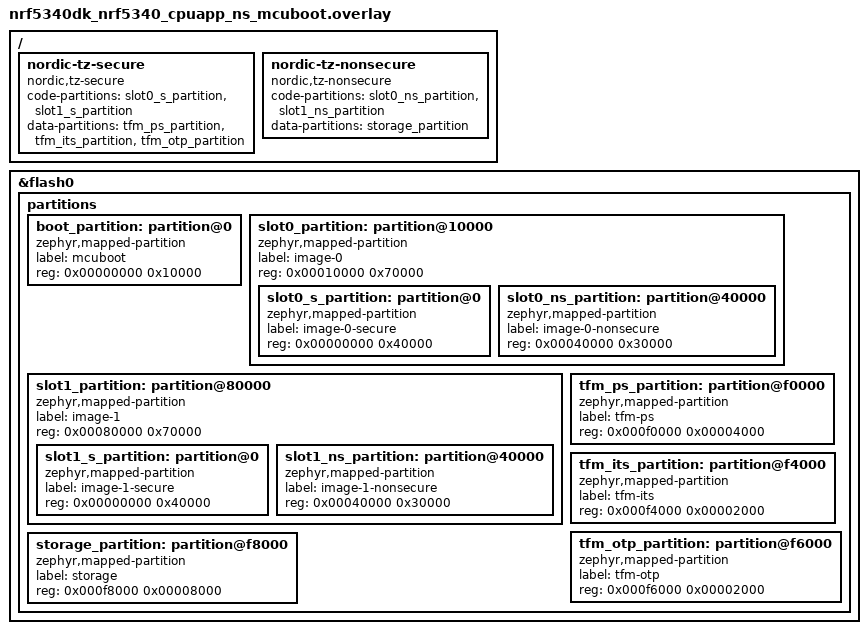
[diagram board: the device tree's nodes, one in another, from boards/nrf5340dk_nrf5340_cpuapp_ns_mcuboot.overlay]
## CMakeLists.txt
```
#
# Copyright (c) 2021 Nordic Semiconductor ASA
#
# SPDX-License-Identifier: LicenseRef-Nordic-5-Clause
#

cmake_minimum_required(VERSION 3.20.0)

if(NOT crypto_service IN_LIST SNIPPET)
  set(SNIPPET crypto_service ${SNIPPET} CACHE STRING "" FORCE)
endif()

find_package(Zephyr REQUIRED HINTS $ENV{ZEPHYR_BASE})

project(sha256)

target_sources(app PRIVATE
        src/main.c)
```

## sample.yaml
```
sample:
  description: |
    This sample demonstrates hash computation and verification using the SHA-256 hash algorithm.
  name: SHA-256 sample
common:
  sysbuild: true
  tags:
    - introduction
    - psa
    - sysbuild
    - ci_samples_crypto
    - crypto
  harness: console
  harness_config:
    type: multi_line
    regex:
      - ".*Example finished successfully!.*"
tests:
  sample.sha256.cc3xx:
    tags:
      - cc3xx
    platform_allow:
      - nrf5340dk/nrf5340/cpuapp/ns
      - nrf5340dk/nrf5340/cpuapp
      - nrf9151dk/nrf9151
      - nrf9151dk/nrf9151/ns
    integration_platforms:
      - nrf5340dk/nrf5340/cpuapp/ns
      - nrf5340dk/nrf5340/cpuapp
      - nrf9151dk/nrf9151
      - nrf9151dk/nrf9151/ns
  sample.sha256.oberon:
    extra_args:
      - CONFIG_PSA_CRYPTO_DRIVER_OBERON=y
      - CONFIG_PSA_CRYPTO_DRIVER_CRACEN=n
    tags:
      - oberon
    platform_allow:
      - nrf5340dk/nrf5340/cpunet
      - nrf54l15dk/nrf54l15/cpuapp
    integration_platforms:
      - nrf5340dk/nrf5340/cpunet
      - nrf54l15dk/nrf54l15/cpuapp
  sample.sha256.cracen:
    tags:
      - cracen
    platform_allow:
      - nrf54l15dk/nrf54l15/cpuapp
      - nrf54l15dk/nrf54l15/cpuapp/ns
      - nrf54l15dk/nrf54l10/cpuapp
      - nrf54l15dk/nrf54l10/cpuapp/ns
      - nrf54l15dk/nrf54l05/cpuapp
      - nrf54ls05dk/nrf54ls05a/cpuapp
      - nrf54ls05dk/nrf54ls05b/cpuapp
      - nrf54lm20dk/nrf54lm20a/cpuapp
      - nrf54lm20dk/nrf54lm20a/cpuapp/ns
      - nrf54lm20dk/nrf54lm20b/cpuapp
      - nrf54lm20dk/nrf54lm20b/cpuapp/ns
      - nrf54lv10dk/nrf54lv10a/cpuapp
      - nrf54lv10dk/nrf54lv10a/cpuapp/ns
      - nrf54lc10dk/nrf54lc10a/cpuapp
      - nrf54lc10dk/nrf54lc10a/cpuapp/ns
      - nrf7120dk/nrf7120/cpuapp
      - nrf7120dk/nrf7120/cpuapp/ns
    integration_platforms:
      - nrf54l15dk/nrf54l15/cpuapp
      - nrf54l15dk/nrf54l15/cpuapp/ns
      - nrf54l15dk/nrf54l10/cpuapp
      - nrf54l15dk/nrf54l10/cpuapp/ns
      - nrf54l15dk/nrf54l05/cpuapp
      - nrf54ls05dk/nrf54ls05a/cpuapp
      - nrf54ls05dk/nrf54ls05b/cpuapp
      - nrf54lm20dk/nrf54lm20a/cpuapp
      - nrf54lm20dk/nrf54lm20a/cpuapp/ns
      - nrf54lm20dk/nrf54lm20b/cpuapp
      - nrf54lm20dk/nrf54lm20b/cpuapp/ns
      - nrf54lv10dk/nrf54lv10a/cpuapp
      - nrf54lv10dk/nrf54lv10a/cpuapp/ns
      - nrf54lc10dk/nrf54lc10a/cpuapp
      - nrf54lc10dk/nrf54lc10a/cpuapp/ns
      - nrf7120dk/nrf7120/cpuapp
      - nrf7120dk/nrf7120/cpuapp/ns
  # Build integration regression protection.
  sample.nrf_security.sha256.integration:
    build_only: true
    extra_args: SB_CONFIG_BOOTLOADER_MCUBOOT=y
    platform_allow:
      - nrf54ls05dk/nrf54ls05b/cpuapp
    integration_platforms:
      - nrf54ls05dk/nrf54ls05b/cpuapp
  # nRF5340 ns needs an MCUboot-compatible flash layout overlay, since the
  # default board overlay (no-MCUboot) reclaims the boot_partition region.
  sample.nrf_security.sha256.integration.nrf5340:
    build_only: true
    extra_args:
      - SB_CONFIG_BOOTLOADER_MCUBOOT=y
      - sha256_EXTRA_DTC_OVERLAY_FILE="boards/nrf5340dk_nrf5340_cpuapp_ns_mcuboot.overlay"
    platform_allow:
      - nrf5340dk/nrf5340/cpuapp/ns
    integration_platforms:
      - nrf5340dk/nrf5340/cpuapp/ns
  sample.newlib_libc.sha256:
    build_only: true
    extra_args: CONFIG_NEWLIB_LIBC=y
    platform_allow:
      - nrf5340dk/nrf5340/cpuapp/ns
      - nrf54h20dk/nrf54h20/cpuapp
    integration_platforms:
      - nrf5340dk/nrf5340/cpuapp/ns
      - nrf54h20dk/nrf54h20/cpuapp
  sample.nrf_security.sha256.integration.rsa:
    build_only: true
    extra_args:
      - SB_CONFIG_BOOTLOADER_MCUBOOT=y
      - SB_CONFIG_BOOT_SIGNATURE_TYPE_RSA=y
      - SB_CONFIG_BOOT_ENCRYPTION=y
    platform_allow:
      - nrf5340dk/nrf5340/cpuapp
      - nrf54l15dk/nrf54l15/cpuapp
    integration_platforms:
      - nrf5340dk/nrf5340/cpuapp
      - nrf54l15dk/nrf54l15/cpuapp
    tags:
      - sysbuild
  sample.sha256.cracen.crypto_service:
    sysbuild: true
    tags:
      - cracen
    platform_allow:
      - nrf54h20dk/nrf54h20/cpuapp
      - nrf9251dk/nrf9251/cpuapp
    integration_platforms:
      - nrf54h20dk/nrf54h20/cpuapp
      - nrf9251dk/nrf9251/cpuapp
```

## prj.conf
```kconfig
#
# Copyright (c) 2024 Nordic Semiconductor ASA
#
# SPDX-License-Identifier: LicenseRef-Nordic-5-Clause
#
# The Zephyr CMSIS emulation assumes that ticks are ms, currently
CONFIG_SYS_CLOCK_TICKS_PER_SEC=1000

CONFIG_MAIN_STACK_SIZE=4096
CONFIG_HEAP_MEM_POOL_SIZE=4096

# Enable logging
CONFIG_CONSOLE=y
CONFIG_LOG=y

# Enable cryptographic features
CONFIG_PSA_CRYPTO=y
CONFIG_PSA_WANT_ALG_SHA_256=y
```

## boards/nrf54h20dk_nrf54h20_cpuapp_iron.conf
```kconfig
#
# Copyright (c) 2024 Nordic Semiconductor
#
# SPDX-License-Identifier: LicenseRef-Nordic-5-Clause
#

# Disable Oberon PSA crypto drivers
CONFIG_PSA_CRYPTO_DRIVER_OBERON=n

# Enable PSA crypto from SSF client
CONFIG_PSA_SSF_CRYPTO_CLIENT=y

# Mbedtls configuration
CONFIG_MBEDTLS_ENABLE_HEAP=y
CONFIG_MBEDTLS_HEAP_SIZE=8192
```

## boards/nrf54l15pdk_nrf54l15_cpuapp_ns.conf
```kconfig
CONFIG_TFM_PROFILE_TYPE_NOT_SET=y

CONFIG_PSA_CRYPTO_DRIVER_OBERON=n
CONFIG_PSA_CRYPTO_DRIVER_CRACEN=y
```

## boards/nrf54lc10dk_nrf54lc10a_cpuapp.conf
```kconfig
# Copyright (c) 2024 Nordic Semiconductor ASA
#
# SPDX-License-Identifier: LicenseRef-Nordic-5-Clause

CONFIG_PSA_CRYPTO_DRIVER_OBERON=n
CONFIG_PSA_CRYPTO_DRIVER_CRACEN=y

CONFIG_MBEDTLS_ENABLE_HEAP=y
CONFIG_MBEDTLS_HEAP_SIZE=8192
```

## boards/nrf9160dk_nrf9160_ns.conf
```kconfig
#
# Copyright (c) 2024 Nordic Semiconductor ASA
#
# SPDX-License-Identifier: LicenseRef-Nordic-5-Clause
#

# Using hardware crypto accelerator
CONFIG_PSA_CRYPTO_DRIVER_CC3XX=y
```

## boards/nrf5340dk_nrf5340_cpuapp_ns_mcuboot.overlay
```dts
/delete-node/ &slot0_s_partition;
/delete-node/ &slot0_ns_partition;
/delete-node/ &tfm_its_partition;
/delete-node/ &tfm_otp_partition;
/delete-node/ &tfm_ps_partition;
/delete-node/ &tfm_storage_partition;

&flash0 {
	partitions {
		boot_partition: partition@0 {
			compatible = "zephyr,mapped-partition";
			label = "mcuboot";
			reg = <0x00000000 0x10000>;
		};

		slot0_partition: partition@10000 {
			compatible = "zephyr,mapped-partition";
			label = "image-0";
			reg = <0x00010000 0x70000>;
			ranges = <0x0 0x10000 0x70000>;
			#address-cells = <1>;
			#size-cells = <1>;

			slot0_s_partition: partition@0 {
				compatible = "zephyr,mapped-partition";
				label = "image-0-secure";
				reg = <0x00000000 0x40000>;
			};

			slot0_ns_partition: partition@40000 {
				compatible = "zephyr,mapped-partition";
				label = "image-0-nonsecure";
				reg = <0x00040000 0x30000>;
			};
		};

		slot1_partition: partition@80000 {
			compatible = "zephyr,mapped-partition";
			label = "image-1";
			reg = <0x00080000 0x70000>;
			ranges = <0x0 0x80000 0x70000>;
			#address-cells = <1>;
			#size-cells = <1>;

			slot1_s_partition: partition@0 {
				compatible = "zephyr,mapped-partition";
				label = "image-1-secure";
				reg = <0x00000000 0x40000>;
			};

			slot1_ns_partition: partition@40000 {
				compatible = "zephyr,mapped-partition";
				label = "image-1-nonsecure";
				reg = <0x00040000 0x30000>;
			};
		};

		tfm_ps_partition: partition@f0000 {
			compatible = "zephyr,mapped-partition";
			label = "tfm-ps";
			reg = <0x000f0000 0x00004000>;
		};

		tfm_its_partition: partition@f4000 {
			compatible = "zephyr,mapped-partition";
			label = "tfm-its";
			reg = <0x000f4000 0x00002000>;
		};

		tfm_otp_partition: partition@f6000 {
			compatible = "zephyr,mapped-partition";
			label = "tfm-otp";
			reg = <0x000f6000 0x00002000>;
		};

		storage_partition: partition@f8000 {
			compatible = "zephyr,mapped-partition";
			label = "storage";
			reg = <0x000f8000 0x00008000>;
		};
	};
};

/ {
	/delete-node/ nordic-tz-secure;
	/delete-node/ nordic-tz-nonsecure;

	nordic-tz-secure {
		compatible = "nordic,tz-secure";
		code-partitions = <&slot0_s_partition>,
				  <&slot1_s_partition>;
		data-partitions = <&tfm_ps_partition>,
				  <&tfm_its_partition>,
				  <&tfm_otp_partition>;
	};

	nordic-tz-nonsecure {
		compatible = "nordic,tz-nonsecure";
		code-partitions = <&slot0_ns_partition>,
				  <&slot1_ns_partition>;
		data-partitions = <&storage_partition>;
	};
};
```

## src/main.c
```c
/*
 * Copyright (c) 2021 Nordic Semiconductor ASA
 *
 * SPDX-License-Identifier: LicenseRef-Nordic-5-Clause
 */

#include <zephyr/kernel.h>
#include <zephyr/sys/printk.h>
#include <zephyr/sys/util.h>
#include <stdio.h>
#include <stdlib.h>
#include <string.h>
#include <psa/crypto.h>
#include <zephyr/logging/log.h>

#ifdef CONFIG_BUILD_WITH_TFM
#include <tfm_ns_interface.h>
#endif

#define APP_SUCCESS		(0)
#define APP_ERROR		(-1)
#define APP_SUCCESS_MESSAGE "Example finished successfully!"
#define APP_ERROR_MESSAGE "Example exited with error!"

#define PRINT_HEX(p_label, p_text, len)\
	({\
		LOG_INF("---- %s (len: %u): ----", p_label, len);\
		LOG_HEXDUMP_INF(p_text, len, "Content:");\
		LOG_INF("---- %s end  ----", p_label);\
	})

LOG_MODULE_REGISTER(sha256, LOG_LEVEL_DBG);

/* ====================================================================== */
/*				Global variables/defines for the SHA256 example			  */

#define NRF_CRYPTO_EXAMPLE_SHA256_TEXT_SIZE (150)
#define NRF_CRYPTO_EXAMPLE_SHA256_SIZE (32)

/* Below text is used as plaintext for computing/verifying the hash. */
static uint8_t m_plain_text[NRF_CRYPTO_EXAMPLE_SHA256_TEXT_SIZE] = {
	"Example string to demonstrate basic usage of SHA256."
	"That uses single and multi-part PSA crypto API's to "
	"perform a SHA-256 hashing operation."
};

static uint8_t m_hash[NRF_CRYPTO_EXAMPLE_SHA256_SIZE];

/* ====================================================================== */

int crypto_init(void)
{
	psa_status_t status;

	/* Initialize PSA Crypto */
	status = psa_crypto_init();
	if (status != PSA_SUCCESS) {
		return APP_ERROR;
	}

	return APP_SUCCESS;
}

int hash_singlepart_sha256(void)
{
	uint32_t olen;
	psa_status_t status;

	LOG_INF("Hashing using SHA-256...");

	/* Calculate the SHA-256 hash */
	status = psa_hash_compute(
		PSA_ALG_SHA_256, m_plain_text, sizeof(m_plain_text), m_hash, sizeof(m_hash), &olen);
	if (status != PSA_SUCCESS) {
		LOG_INF("psa_hash_compute failed! (Error: %d)", status);
		return APP_ERROR;
	}

	LOG_INF("Hash computation successful!");
	PRINT_HEX("SHA-256 hash", m_hash, sizeof(m_hash));

	return APP_SUCCESS;
}

int hash_multipart_sha256(void)
{
	uint32_t olen;
	psa_status_t status;
	uint8_t *input_ptr = m_plain_text;
	psa_hash_operation_t hash_operation = {0};

	LOG_INF("Hashing using multi-part SHA-256...");

	/* Setup a multipart hash operation */
	status = psa_hash_setup(&hash_operation, PSA_ALG_SHA_256);
	if (status != PSA_SUCCESS) {
		LOG_ERR("Could not setup the hash operation! Error %d", status);
		return APP_ERROR;
	}


	/* Feed the chunks of the input data to the PSA driver */
	status = psa_hash_update(&hash_operation, input_ptr, 42);
	if (status != PSA_SUCCESS) {
		LOG_ERR("Could not hash the next chunk! Error %d", status);
		return APP_ERROR;

	}
	LOG_INF("Added %d bytes", 42);
	input_ptr += 42;


	status = psa_hash_update(&hash_operation, input_ptr, 58);
	if (status != PSA_SUCCESS) {
		LOG_ERR("Could not hash the next chunk! Error %d", status);
		return APP_ERROR;

	}
	LOG_INF("Added %d bytes", 58);
	input_ptr += 58;

	status = psa_hash_update(&hash_operation, input_ptr, 50);
	if (status != PSA_SUCCESS) {
		LOG_ERR("Could not hash the next chunk! Error %d", status);
		return APP_ERROR;

	}
	LOG_INF("Added %d bytes", 50);

	status = psa_hash_finish(&hash_operation, m_hash, sizeof(m_hash), &olen);
	if (status != PSA_SUCCESS) {
		LOG_ERR("Could not finish the hash operation! Error %d", status);
		return APP_ERROR;
	}

	LOG_INF("Hash computation successful!");
	PRINT_HEX("SHA-256 hash", m_hash, sizeof(m_hash));

	return APP_SUCCESS;
}

int verify_sha256(void)
{
	psa_status_t status;

	LOG_INF("Verifying the SHA-256 hash...");

	/* Verify the hash */
	status = psa_hash_compare(
		PSA_ALG_SHA_256, m_plain_text, sizeof(m_plain_text), m_hash, sizeof(m_hash));
	if (status != PSA_SUCCESS) {
		LOG_INF("psa_hash_compare failed! (Error: %d)", status);
		return APP_ERROR;
	}

	LOG_INF("SHA-256 verification successful!");

	return APP_SUCCESS;
}

int main(void)
{
	int status;

	LOG_INF("Starting SHA-256 example...");

	status = crypto_init();
	if (status != APP_SUCCESS) {
		LOG_INF(APP_ERROR_MESSAGE);
		return APP_ERROR;
	}

	PRINT_HEX("Plaintext to hash", m_plain_text, sizeof(m_plain_text));

	status = hash_singlepart_sha256();
	if (status != APP_SUCCESS) {
		LOG_INF(APP_ERROR_MESSAGE);
		return APP_ERROR;
	}

	status = verify_sha256();
	if (status != APP_SUCCESS) {
		LOG_INF(APP_ERROR_MESSAGE);
		return APP_ERROR;
	}

	/* Reset the hash */
	memset(m_hash, 0, sizeof(m_hash));

	status = hash_multipart_sha256();
	if (status != APP_SUCCESS) {
		LOG_INF(APP_ERROR_MESSAGE);
		return APP_ERROR;
	}

	status = verify_sha256();
	if (status != APP_SUCCESS) {
		LOG_INF(APP_ERROR_MESSAGE);
		return APP_ERROR;
	}

	LOG_INF(APP_SUCCESS_MESSAGE);

	return APP_SUCCESS;
}
```
